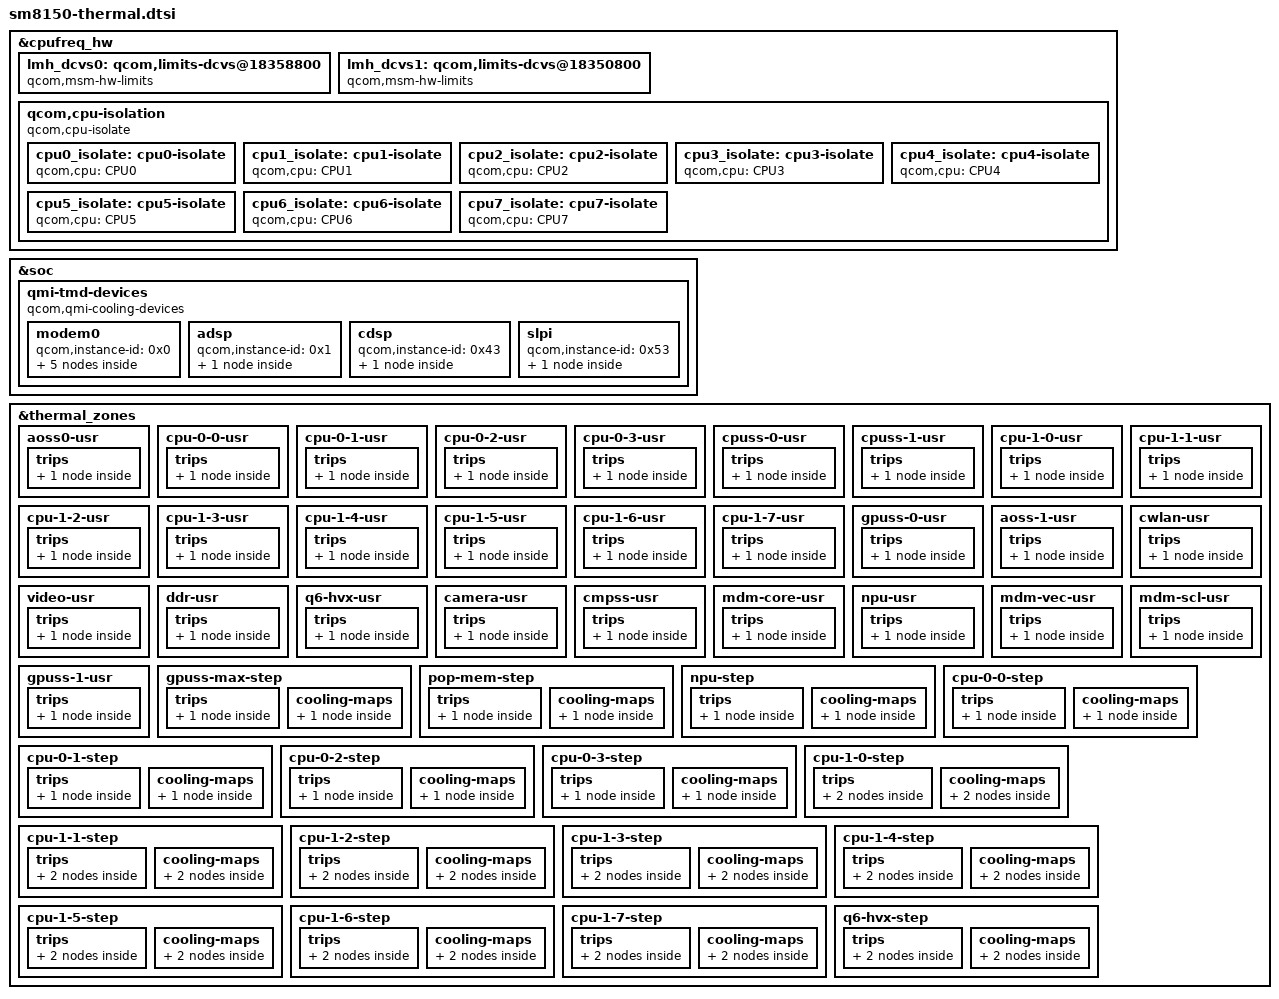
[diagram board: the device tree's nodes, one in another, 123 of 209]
/* Copyright (c) 2018-2019, The Linux Foundation. All rights reserved.
 *
 * This program is free software; you can redistribute it and/or modify
 * it under the terms of the GNU General Public License version 2 and
 * only version 2 as published by the Free Software Foundation.
 *
 * This program is distributed in the hope that it will be useful,
 * but WITHOUT ANY WARRANTY; without even the implied warranty of
 * MERCHANTABILITY or FITNESS FOR A PARTICULAR PURPOSE.  See the
 * GNU General Public License for more details.
 */

#include <dt-bindings/thermal/thermal.h>

&cpufreq_hw {
	#address-cells = <1>;
	#size-cells = <1>;
	lmh_dcvs0: qcom,limits-dcvs@18358800 {
		compatible = "qcom,msm-hw-limits";
		interrupts = <GIC_SPI 32 IRQ_TYPE_LEVEL_HIGH>;
		qcom,affinity = <0>;
		reg = <0x18358800 0x1000>,
			<0x18323000 0x1000>;
	};

	lmh_dcvs1: qcom,limits-dcvs@18350800 {
		compatible = "qcom,msm-hw-limits";
		interrupts = <GIC_SPI 33 IRQ_TYPE_LEVEL_HIGH>;
		qcom,affinity = <1>;
		reg = <0x18350800 0x1000>,
			<0x18325800 0x1000>;
		isens_vref_0p8-supply = <&pm8150_l5_ao>;
		isens-vref-0p8-settings = <880000 880000 20000>;
		isens_vref_1p8-supply = <&pm8150_l12_ao>;
		isens-vref-1p8-settings = <1800000 1800000 20000>;
	};

	qcom,cpu-isolation {
		compatible = "qcom,cpu-isolate";
		cpu0_isolate: cpu0-isolate {
			qcom,cpu = <&CPU0>;
			#cooling-cells = <2>;
		};

		cpu1_isolate: cpu1-isolate {
			qcom,cpu = <&CPU1>;
			#cooling-cells = <2>;
		};

		cpu2_isolate: cpu2-isolate {
			qcom,cpu = <&CPU2>;
			#cooling-cells = <2>;
		};

		cpu3_isolate: cpu3-isolate {
			qcom,cpu = <&CPU3>;
			#cooling-cells = <2>;
		};

		cpu4_isolate: cpu4-isolate {
			qcom,cpu = <&CPU4>;
			#cooling-cells = <2>;
		};

		cpu5_isolate: cpu5-isolate {
			qcom,cpu = <&CPU5>;
			#cooling-cells = <2>;
		};

		cpu6_isolate: cpu6-isolate {
			qcom,cpu = <&CPU6>;
			#cooling-cells = <2>;
		};

		cpu7_isolate: cpu7-isolate {
			qcom,cpu = <&CPU7>;
			#cooling-cells = <2>;
		};
	};
};

&soc {
	qmi-tmd-devices {
		compatible = "qcom,qmi-cooling-devices";

		modem0 {
			qcom,instance-id = <0x0>;

			modem0_pa: modem0_pa {
				qcom,qmi-dev-name = "pa";
				#cooling-cells = <2>;
			};

			modem0_proc: modem0_proc {
				qcom,qmi-dev-name = "modem";
				#cooling-cells = <2>;
			};

			modem0_current: modem0_current {
				qcom,qmi-dev-name = "modem_current";
				#cooling-cells = <2>;
			};

			modem0_skin: modem0_skin {
				qcom,qmi-dev-name = "modem_skin";
				#cooling-cells = <2>;
			};

			modem0_vdd: modem0_vdd {
				qcom,qmi-dev-name = "cpuv_restriction_cold";
				#cooling-cells = <2>;
			};
		};

		adsp {
			qcom,instance-id = <0x1>;

			adsp_vdd: adsp_vdd {
				qcom,qmi-dev-name = "cpuv_restriction_cold";
				#cooling-cells = <2>;
			};
		};

		cdsp {
			qcom,instance-id = <0x43>;

			cdsp_vdd: cdsp_vdd {
				qcom,qmi-dev-name = "cpuv_restriction_cold";
				#cooling-cells = <2>;
			};
		};

		slpi {
			qcom,instance-id = <0x53>;

			slpi_vdd: slpi_vdd {
				qcom,qmi-dev-name = "cpuv_restriction_cold";
				#cooling-cells = <2>;
			};
		};
	};
};

&thermal_zones {
	aoss0-usr {
		polling-delay-passive = <0>;
		polling-delay = <0>;
		thermal-governor = "user_space";
		thermal-sensors = <&tsens0 0>;
		wake-capable-sensor;
		trips {
			active-config0 {
				temperature = <125000>;
				hysteresis = <1000>;
				type = "passive";
			};
		};
	};

	cpu-0-0-usr {
		polling-delay-passive = <0>;
		polling-delay = <0>;
		thermal-governor = "user_space";
		thermal-sensors = <&tsens0 1>;
		wake-capable-sensor;
		trips {
			active-config0 {
				temperature = <125000>;
				hysteresis = <1000>;
				type = "passive";
			};
		};
	};

	cpu-0-1-usr {
		polling-delay-passive = <0>;
		polling-delay = <0>;
		thermal-governor = "user_space";
		thermal-sensors = <&tsens0 2>;
		wake-capable-sensor;
		trips {
			active-config0 {
				temperature = <125000>;
				hysteresis = <1000>;
				type = "passive";
			};
		};
	};

	cpu-0-2-usr {
		polling-delay-passive = <0>;
		polling-delay = <0>;
		thermal-governor = "user_space";
		thermal-sensors = <&tsens0 3>;
		wake-capable-sensor;
		trips {
			active-config0 {
				temperature = <125000>;
				hysteresis = <1000>;
				type = "passive";
			};
		};
	};

	cpu-0-3-usr {
		polling-delay-passive = <0>;
		polling-delay = <0>;
		thermal-sensors = <&tsens0 4>;
		thermal-governor = "user_space";
		wake-capable-sensor;
		trips {
			active-config0 {
				temperature = <125000>;
				hysteresis = <1000>;
				type = "passive";
			};
		};
	};

	cpuss-0-usr {
		polling-delay-passive = <0>;
		polling-delay = <0>;
		thermal-sensors = <&tsens0 5>;
		thermal-governor = "user_space";
		wake-capable-sensor;
		trips {
			active-config0 {
				temperature = <125000>;
				hysteresis = <1000>;
				type = "passive";
			};
		};
	};

	cpuss-1-usr {
		polling-delay-passive = <0>;
		polling-delay = <0>;
		thermal-sensors = <&tsens0 6>;
		thermal-governor = "user_space";
		wake-capable-sensor;
		trips {
			active-config0 {
				temperature = <125000>;
				hysteresis = <1000>;
				type = "passive";
			};
		};
	};

	cpu-1-0-usr {
		polling-delay-passive = <0>;
		polling-delay = <0>;
		thermal-sensors = <&tsens0 7>;
		thermal-governor = "user_space";
		wake-capable-sensor;
		trips {
			active-config0 {
				temperature = <125000>;
				hysteresis = <1000>;
				type = "passive";
			};
		};
	};

	cpu-1-1-usr {
		polling-delay-passive = <0>;
		polling-delay = <0>;
		thermal-sensors = <&tsens0 8>;
		thermal-governor = "user_space";
		wake-capable-sensor;
		trips {
			active-config0 {
				temperature = <125000>;
				hysteresis = <1000>;
				type = "passive";
			};
		};
	};

	cpu-1-2-usr {
		polling-delay-passive = <0>;
		polling-delay = <0>;
		thermal-sensors = <&tsens0 9>;
		thermal-governor = "user_space";
		wake-capable-sensor;
		trips {
			active-config0 {
				temperature = <125000>;
				hysteresis = <1000>;
				type = "passive";
			};
		};
	};

	cpu-1-3-usr {
		polling-delay-passive = <0>;
		polling-delay = <0>;
		thermal-sensors = <&tsens0 10>;
		thermal-governor = "user_space";
		wake-capable-sensor;
		trips {
			active-config0 {
				temperature = <125000>;
				hysteresis = <1000>;
				type = "passive";
			};
		};
	};

	cpu-1-4-usr {
		polling-delay-passive = <0>;
		polling-delay = <0>;
		thermal-sensors = <&tsens0 11>;
		thermal-governor = "user_space";
		wake-capable-sensor;
		trips {
			active-config0 {
				temperature = <125000>;
				hysteresis = <1000>;
				type = "passive";
			};
		};
	};

	cpu-1-5-usr {
		polling-delay-passive = <0>;
		polling-delay = <0>;
		thermal-sensors = <&tsens0 12>;
		thermal-governor = "user_space";
		wake-capable-sensor;
		trips {
			active-config0 {
				temperature = <125000>;
				hysteresis = <1000>;
				type = "passive";
			};
		};
	};

	cpu-1-6-usr {
		polling-delay-passive = <0>;
		polling-delay = <0>;
		thermal-sensors = <&tsens0 13>;
		thermal-governor = "user_space";
		wake-capable-sensor;
		trips {
			active-config0 {
				temperature = <125000>;
				hysteresis = <1000>;
				type = "passive";
			};
		};
	};

	cpu-1-7-usr {
		polling-delay-passive = <0>;
		polling-delay = <0>;
		thermal-sensors = <&tsens0 14>;
		thermal-governor = "user_space";
		wake-capable-sensor;
		trips {
			active-config0 {
				temperature = <125000>;
				hysteresis = <1000>;
				type = "passive";
			};
		};
	};

	gpuss-0-usr {
		polling-delay-passive = <0>;
		polling-delay = <0>;
		thermal-sensors = <&tsens0 15>;
		thermal-governor = "user_space";
		wake-capable-sensor;
		trips {
			active-config0 {
				temperature = <125000>;
				hysteresis = <1000>;
				type = "passive";
			};
		};
	};

	aoss-1-usr {
		polling-delay-passive = <0>;
		polling-delay = <0>;
		thermal-sensors = <&tsens1 0>;
		thermal-governor = "user_space";
		wake-capable-sensor;
		trips {
			active-config0 {
				temperature = <125000>;
				hysteresis = <1000>;
				type = "passive";
			};
		};
	};

	cwlan-usr {
		polling-delay-passive = <0>;
		polling-delay = <0>;
		thermal-sensors = <&tsens1 1>;
		thermal-governor = "user_space";
		wake-capable-sensor;
		trips {
			active-config0 {
				temperature = <125000>;
				hysteresis = <1000>;
				type = "passive";
			};
		};
	};

	video-usr {
		polling-delay-passive = <0>;
		polling-delay = <0>;
		thermal-sensors = <&tsens1 2>;
		thermal-governor = "user_space";
		wake-capable-sensor;
		trips {
			active-config0 {
				temperature = <125000>;
				hysteresis = <1000>;
				type = "passive";
			};
		};
	};

	ddr-usr {
		polling-delay-passive = <0>;
		polling-delay = <0>;
		thermal-sensors = <&tsens1 3>;
		thermal-governor = "user_space";
		wake-capable-sensor;
		trips {
			active-config0 {
				temperature = <125000>;
				hysteresis = <1000>;
				type = "passive";
			};
		};
	};

	q6-hvx-usr {
		polling-delay-passive = <0>;
		polling-delay = <0>;
		thermal-sensors = <&tsens1 4>;
		thermal-governor = "user_space";
		wake-capable-sensor;
		trips {
			active-config0 {
				temperature = <125000>;
				hysteresis = <1000>;
				type = "passive";
			};
		};
	};

	camera-usr {
		polling-delay-passive = <0>;
		polling-delay = <0>;
		thermal-sensors = <&tsens1 5>;
		thermal-governor = "user_space";
		wake-capable-sensor;
		trips {
			active-config0 {
				temperature = <125000>;
				hysteresis = <1000>;
				type = "passive";
			};
		};
	};

	cmpss-usr {
		polling-delay-passive = <0>;
		polling-delay = <0>;
		thermal-sensors = <&tsens1 6>;
		thermal-governor = "user_space";
		wake-capable-sensor;
		trips {
			active-config0 {
				temperature = <125000>;
				hysteresis = <1000>;
				type = "passive";
			};
		};
	};

	mdm-core-usr {
		polling-delay-passive = <0>;
		polling-delay = <0>;
		thermal-sensors = <&tsens1 7>;
		thermal-governor = "user_space";
		wake-capable-sensor;
		trips {
			active-config0 {
				temperature = <125000>;
				hysteresis = <1000>;
				type = "passive";
			};
		};
	};

	npu-usr {
		polling-delay-passive = <0>;
		polling-delay = <0>;
		thermal-sensors = <&tsens1 8>;
		thermal-governor = "user_space";
		wake-capable-sensor;
		trips {
			active-config0 {
				temperature = <125000>;
				hysteresis = <1000>;
				type = "passive";
			};
		};
	};

	mdm-vec-usr {
		polling-delay-passive = <0>;
		polling-delay = <0>;
		thermal-sensors = <&tsens1 9>;
		thermal-governor = "user_space";
		wake-capable-sensor;
		trips {
			active-config0 {
				temperature = <125000>;
				hysteresis = <1000>;
				type = "passive";
			};
		};
	};

	mdm-scl-usr {
		polling-delay-passive = <0>;
		polling-delay = <0>;
		thermal-sensors = <&tsens1 10>;
		thermal-governor = "user_space";
		wake-capable-sensor;
		trips {
			active-config0 {
				temperature = <125000>;
				hysteresis = <1000>;
				type = "passive";
			};
		};
	};

	gpuss-1-usr {
		polling-delay-passive = <0>;
		polling-delay = <0>;
		thermal-governor = "user_space";
		thermal-sensors = <&tsens1 11>;
		wake-capable-sensor;
		trips {
			active-config0 {
				temperature = <125000>;
				hysteresis = <1000>;
				type = "passive";
			};
		};
	};

	gpuss-max-step {
		polling-delay-passive = <10>;
		polling-delay = <100>;
		thermal-governor = "step_wise";
		wake-capable-sensor;
		trips {
			gpu_trip0: gpu-trip0 {
				temperature = <85000>;
				hysteresis = <0>;
				type = "passive";
			};
		};

		cooling-maps {
			gpu_cdev {
				trip = <&gpu_trip0>;
				cooling-device = <&msm_gpu THERMAL_NO_LIMIT
							THERMAL_NO_LIMIT>;
			};
		};
	};

	pop-mem-step {
		polling-delay-passive = <10>;
		polling-delay = <0>;
		thermal-sensors = <&tsens1 3>;
		thermal-governor = "step_wise";
		wake-capable-sensor;
		trips {
			pop_trip: pop-trip {
				temperature = <95000>;
				hysteresis = <0>;
				type = "passive";
			};
		};

		cooling-maps {
			pop_cdev4 {
				trip = <&pop_trip>;
				cooling-device =
					<&CPU4 THERMAL_NO_LIMIT
						THERMAL_NO_LIMIT>;
			};
		};
	};

	npu-step {
		polling-delay-passive = <10>;
		polling-delay = <0>;
		thermal-sensors = <&tsens1 8>;
		thermal-governor = "step_wise";
		wake-capable-sensor;
		trips {
			npu_trip0: npu-trip0 {
				temperature = <95000>;
				hysteresis = <0>;
				type = "passive";
			};
		};

		cooling-maps {
			npu_cdev {
				trip = <&npu_trip0>;
				cooling-device =
					<&msm_npu THERMAL_NO_LIMIT
						THERMAL_NO_LIMIT>;
			};
		};
	};

	cpu-0-0-step {
		polling-delay-passive = <0>;
		polling-delay = <0>;
		thermal-governor = "step_wise";
		thermal-sensors = <&tsens0 1>;
		wake-capable-sensor;
		trips {
			cpu00_config: cpu00-config {
				temperature = <110000>;
				hysteresis = <10000>;
				type = "passive";
			};
		};

		cooling-maps {
			cpu00_cdev {
				trip = <&cpu00_config>;
				cooling-device = <&cpu0_isolate 1 1>;
			};
		};
	};

	cpu-0-1-step {
		polling-delay-passive = <0>;
		polling-delay = <0>;
		thermal-governor = "step_wise";
		thermal-sensors = <&tsens0 2>;
		wake-capable-sensor;
		trips {
			cpu01_config: cpu01-config {
				temperature = <110000>;
				hysteresis = <10000>;
				type = "passive";
			};
		};

		cooling-maps {
			cpu01_cdev {
				trip = <&cpu01_config>;
				cooling-device = <&cpu1_isolate 1 1>;
			};
		};
	};

	cpu-0-2-step {
		polling-delay-passive = <0>;
		polling-delay = <0>;
		thermal-governor = "step_wise";
		thermal-sensors = <&tsens0 3>;
		wake-capable-sensor;
		trips {
			cpu02_config: cpu02-config {
				temperature = <110000>;
				hysteresis = <10000>;
				type = "passive";
			};
		};

		cooling-maps {
			cpu02_cdev {
				trip = <&cpu02_config>;
				cooling-device = <&cpu2_isolate 1 1>;
			};
		};
	};

	cpu-0-3-step {
		polling-delay-passive = <0>;
		polling-delay = <0>;
		thermal-sensors = <&tsens0 4>;
		thermal-governor = "step_wise";
		wake-capable-sensor;
		trips {
			cpu03_config: cpu03-config {
				temperature = <110000>;
				hysteresis = <10000>;
				type = "passive";
			};
		};

		cooling-maps {
			cpu03_cdev {
				trip = <&cpu03_config>;
				cooling-device = <&cpu3_isolate 1 1>;
			};
		};
	};

	cpu-1-0-step {
		polling-delay-passive = <0>;
		polling-delay = <0>;
		thermal-sensors = <&tsens0 7>;
		thermal-governor = "step_wise";
		wake-capable-sensor;
		trips {
			cpufreq_10_config: cpufreq-10-config {
				temperature = <75000>;
				hysteresis = <5000>;
				type = "passive";
			};

			cpu10_config: cpu10-config {
				temperature = <110000>;
				hysteresis = <10000>;
				type = "passive";
			};
		};

		cooling-maps {
			cpufreq_cdev {
				trip = <&cpufreq_10_config>;
				cooling-device = <&cpu7_notify 1 1>;
			};

			cpu10_cdev {
				trip = <&cpu10_config>;
				cooling-device = <&cpu4_isolate 1 1>;
			};
		};
	};

	cpu-1-1-step {
		polling-delay-passive = <0>;
		polling-delay = <0>;
		thermal-sensors = <&tsens0 8>;
		thermal-governor = "step_wise";
		wake-capable-sensor;
		trips {
			cpufreq_11_config: cpufreq-11-config {
				temperature = <75000>;
				hysteresis = <5000>;
				type = "passive";
			};

			cpu11_config: cpu11-config {
				temperature = <110000>;
				hysteresis = <10000>;
				type = "passive";
			};
		};

		cooling-maps {
			cpufreq_cdev {
				trip = <&cpufreq_11_config>;
				cooling-device = <&cpu7_notify 1 1>;
			};

			cpu11_cdev {
				trip = <&cpu11_config>;
				cooling-device = <&cpu5_isolate 1 1>;
			};
		};
	};

	cpu-1-2-step {
		polling-delay-passive = <0>;
		polling-delay = <0>;
		thermal-sensors = <&tsens0 9>;
		thermal-governor = "step_wise";
		wake-capable-sensor;
		trips {
			cpufreq_12_config: cpufreq-12-config {
				temperature = <75000>;
				hysteresis = <5000>;
				type = "passive";
			};

			cpu12_config: cpu12-config {
				temperature = <110000>;
				hysteresis = <10000>;
				type = "passive";
			};
		};

		cooling-maps {
			cpufreq_cdev {
				trip = <&cpufreq_12_config>;
				cooling-device = <&cpu7_notify 1 1>;
			};

			cpu12_cdev {
				trip = <&cpu12_config>;
				cooling-device = <&cpu6_isolate 1 1>;
			};
		};
	};

	cpu-1-3-step {
		polling-delay-passive = <0>;
		polling-delay = <0>;
		thermal-sensors = <&tsens0 10>;
		thermal-governor = "step_wise";
		wake-capable-sensor;
		trips {
			cpufreq_13_config: cpufreq-13-config {
				temperature = <75000>;
				hysteresis = <5000>;
				type = "passive";
			};

			cpu13_config: cpu13-config {
				temperature = <110000>;
				hysteresis = <10000>;
				type = "passive";
			};
		};

		cooling-maps {
			cpufreq_cdev {
				trip = <&cpufreq_13_config>;
				cooling-device = <&cpu7_notify 1 1>;
			};

			cpu13_cdev {
				trip = <&cpu13_config>;
				cooling-device = <&cpu7_isolate 1 1>;
			};
		};
	};

	cpu-1-4-step {
		polling-delay-passive = <0>;
		polling-delay = <0>;
		thermal-sensors = <&tsens0 11>;
		thermal-governor = "step_wise";
		wake-capable-sensor;
		trips {
			cpufreq_14_config: cpufreq-14-config {
				temperature = <75000>;
				hysteresis = <5000>;
				type = "passive";
			};

			cpu14_config: cpu14-config {
				temperature = <110000>;
				hysteresis = <10000>;
				type = "passive";
			};
		};

		cooling-maps {
			cpufreq_cdev {
				trip = <&cpufreq_14_config>;
				cooling-device = <&cpu7_notify 1 1>;
			};

			cpu14_cdev {
				trip = <&cpu14_config>;
				cooling-device = <&cpu4_isolate 1 1>;
			};
		};
	};

	cpu-1-5-step {
		polling-delay-passive = <0>;
		polling-delay = <0>;
		thermal-sensors = <&tsens0 12>;
		thermal-governor = "step_wise";
		wake-capable-sensor;
		trips {
			cpufreq_15_config: cpufreq-15-config {
				temperature = <75000>;
				hysteresis = <5000>;
				type = "passive";
			};

			cpu15_config: cpu15-config {
				temperature = <110000>;
				hysteresis = <10000>;
				type = "passive";
			};
		};

		cooling-maps {
			cpufreq_cdev {
				trip = <&cpufreq_15_config>;
				cooling-device = <&cpu7_notify 1 1>;
			};

			cpu15_cdev {
				trip = <&cpu15_config>;
				cooling-device = <&cpu5_isolate 1 1>;
			};
		};
	};

	cpu-1-6-step {
		polling-delay-passive = <0>;
		polling-delay = <0>;
		thermal-sensors = <&tsens0 13>;
		thermal-governor = "step_wise";
		wake-capable-sensor;
		trips {
			cpufreq_16_config: cpufreq-16-config {
				temperature = <75000>;
				hysteresis = <5000>;
				type = "passive";
			};

			cpu16_config: cpu16-config {
				temperature = <110000>;
				hysteresis = <10000>;
				type = "passive";
			};
		};

		cooling-maps {
			cpufreq_cdev {
				trip = <&cpufreq_16_config>;
				cooling-device = <&cpu7_notify 1 1>;
			};

			cpu16_cdev {
				trip = <&cpu16_config>;
				cooling-device = <&cpu6_isolate 1 1>;
			};
		};
	};

	cpu-1-7-step {
		polling-delay-passive = <0>;
		polling-delay = <0>;
		thermal-sensors = <&tsens0 14>;
		thermal-governor = "step_wise";
		wake-capable-sensor;
		trips {
			cpufreq_17_config: cpufreq-17-config {
				temperature = <75000>;
				hysteresis = <5000>;
				type = "passive";
			};

			cpu17_config: cpu17-config {
				temperature = <110000>;
				hysteresis = <10000>;
				type = "passive";
			};
		};

		cooling-maps {
			cpufreq_cdev {
				trip = <&cpufreq_17_config>;
				cooling-device = <&cpu7_notify 1 1>;
			};

			cpu17_cdev {
				trip = <&cpu17_config>;
				cooling-device = <&cpu7_isolate 1 1>;
			};
		};
	};

	q6-hvx-step {
		polling-delay-passive = <10>;
		polling-delay = <0>;
		thermal-sensors = <&tsens1 4>;
		thermal-governor = "step_wise";
		wake-capable-sensor;
		trips {
			q6_hvx_step0: q6-hvx-step0 {
				temperature = <95000>;
				hysteresis = <0>;
				type = "passive";
			};

			q6_hvx_step1: q6-hvx-step1 {
				temperature = <105000>;
				hysteresis = <5000>;
				type = "passive";
			};
		};

		cooling-maps {
			hvx_cdev_lvl0 {
				trip = <&q6_hvx_step0>;
				cooling-device = <&msm_cdsp_rm
						THERMAL_NO_LIMIT 6>;
			};

			hvx_cdev_lvl1 {
				trip = <&q6_hvx_step1>;
				cooling-device = <&msm_cdsp_rm 6 6>;
			};
		};
	};
};
